# ESP32-C6 register map
Vendor: ESPRESSIF SYSTEMS (SHANGHAI) CO., LTD.; Series: ESP32 C-Series; File version: 12
CPU: RV32IMAC r0p0, little endian, no MPU, no FPU, 0 interrupt priority bits
Address unit: 32 bits
Registers are 32-bit, read-write, reset 0x0 unless marked. A register's access mark holds for its fields unless they carry their own. Offsets are from the block's base; [hi:lo] are bit positions.

## APB_SARADC — SAR (Successive Approximation Register) Analog-to-Digital Converter
Base 0x6000E000
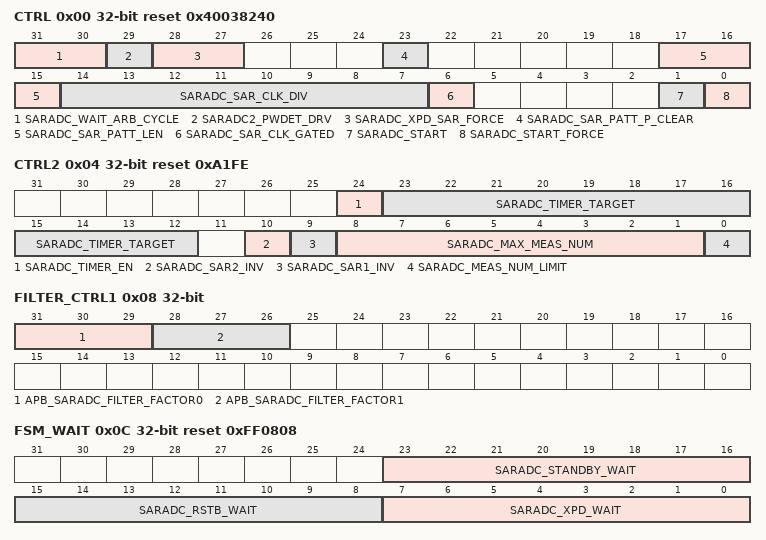
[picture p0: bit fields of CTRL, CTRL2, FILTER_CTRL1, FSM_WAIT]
0x00 CTRL reset 0x40038240 — digital saradc configure register
  [31:30] SARADC_WAIT_ARB_CYCLE — wait arbit signal stable after sar_done
  [29] SARADC2_PWDET_DRV — enable saradc2 power detect driven func.
  [28:27] SARADC_XPD_SAR_FORCE — force option to xpd sar blocks
  [23] SARADC_SAR_PATT_P_CLEAR — clear the pointer of pattern table for DIG ADC1 CTRL
  [17:15] SARADC_SAR_PATT_LEN — 0 ~ 15 means length 1 ~ 16
  [14:7] SARADC_SAR_CLK_DIV — SAR clock divider
  [6] SARADC_SAR_CLK_GATED — SAR clock gated
  [1] SARADC_START — software enable saradc sample
  [0] SARADC_START_FORCE — select software enable saradc sample
0x04 CTRL2 reset 0xA1FE — digital saradc configure register
  [24] SARADC_TIMER_EN — to enable saradc timer trigger
  [23:12] SARADC_TIMER_TARGET — to set saradc timer target
  [10] SARADC_SAR2_INV — 1: data to DIG ADC2 CTRL is inverted, otherwise not
  [9] SARADC_SAR1_INV — 1: data to DIG ADC1 CTRL is inverted, otherwise not
  [8:1] SARADC_MAX_MEAS_NUM — max conversion number
  [0] SARADC_MEAS_NUM_LIMIT — enable max meas num
0x08 FILTER_CTRL1 — digital saradc configure register
  [31:29] APB_SARADC_FILTER_FACTOR0 — Factor of saradc filter0
  [28:26] APB_SARADC_FILTER_FACTOR1 — Factor of saradc filter1
0x0C FSM_WAIT reset 0xFF0808 — digital saradc configure register
  [23:16] SARADC_STANDBY_WAIT, [15:8] SARADC_RSTB_WAIT, [7:0] SARADC_XPD_WAIT
0x10 SAR1_STATUS ro reset 0x20000000 — digital saradc configure register
  [31:0] SARADC_SAR1_STATUS — saradc1 status about data and channel
0x14 SAR2_STATUS ro reset 0x20000000 — digital saradc configure register
  [31:0] SARADC_SAR2_STATUS — saradc2 status about data and channel
0x18 SAR_PATT_TAB1 reset 0xFFFFFF — digital saradc configure register
  [23:0] SARADC_SAR_PATT_TAB1 — item 0 ~ 3 for pattern table 1 (each item one byte)
0x1C SAR_PATT_TAB2 reset 0xFFFFFF — digital saradc configure register
  [23:0] SARADC_SAR_PATT_TAB2 — Item 4 ~ 7 for pattern table 1 (each item one byte)
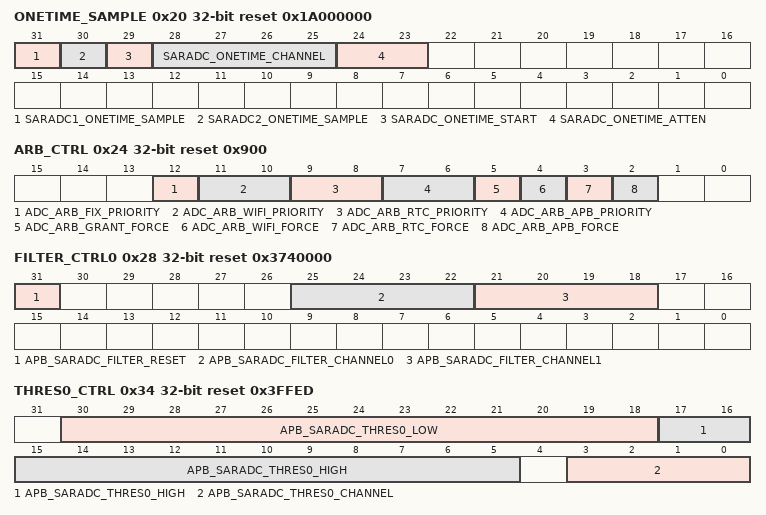
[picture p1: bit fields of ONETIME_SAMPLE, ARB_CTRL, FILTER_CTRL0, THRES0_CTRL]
0x20 ONETIME_SAMPLE reset 0x1A000000 — digital saradc configure register
  [31] SARADC1_ONETIME_SAMPLE — enable adc1 onetime sample
  [30] SARADC2_ONETIME_SAMPLE — enable adc2 onetime sample
  [29] SARADC_ONETIME_START — trigger adc onetime sample
  [28:25] SARADC_ONETIME_CHANNEL — configure onetime channel
  [24:23] SARADC_ONETIME_ATTEN — configure onetime atten
0x24 ARB_CTRL reset 0x900 — digital saradc configure register
  [12] ADC_ARB_FIX_PRIORITY — adc2 arbiter uses fixed priority
  [11:10] ADC_ARB_WIFI_PRIORITY — Set adc2 arbiter wifi priority
  [9:8] ADC_ARB_RTC_PRIORITY — Set adc2 arbiter rtc priority
  [7:6] ADC_ARB_APB_PRIORITY — Set adc2 arbiterapb priority
  [5] ADC_ARB_GRANT_FORCE — adc2 arbiter force grant
  [4] ADC_ARB_WIFI_FORCE — adc2 arbiter force to enable wifi controller
  [3] ADC_ARB_RTC_FORCE — adc2 arbiter force to enable rtc controller
  [2] ADC_ARB_APB_FORCE — adc2 arbiter force to enableapb controller
0x28 FILTER_CTRL0 reset 0x3740000 — digital saradc configure register
  [31] APB_SARADC_FILTER_RESET — enable apb_adc1_filter
  [25:22] APB_SARADC_FILTER_CHANNEL0 — configure filter0 to adc channel
  [21:18] APB_SARADC_FILTER_CHANNEL1 — configure filter1 to adc channel
0x2C SAR1DATA_STATUS ro — digital saradc configure register
  [16:0] APB_SARADC1_DATA — saradc1 data
0x30 SAR2DATA_STATUS ro — digital saradc configure register
  [16:0] APB_SARADC2_DATA — saradc2 data
0x34 THRES0_CTRL reset 0x3FFED — digital saradc configure register
  [30:18] APB_SARADC_THRES0_LOW — saradc thres0 monitor thres
  [17:5] APB_SARADC_THRES0_HIGH — saradc thres0 monitor thres
  [3:0] APB_SARADC_THRES0_CHANNEL — configure thres0 to adc channel
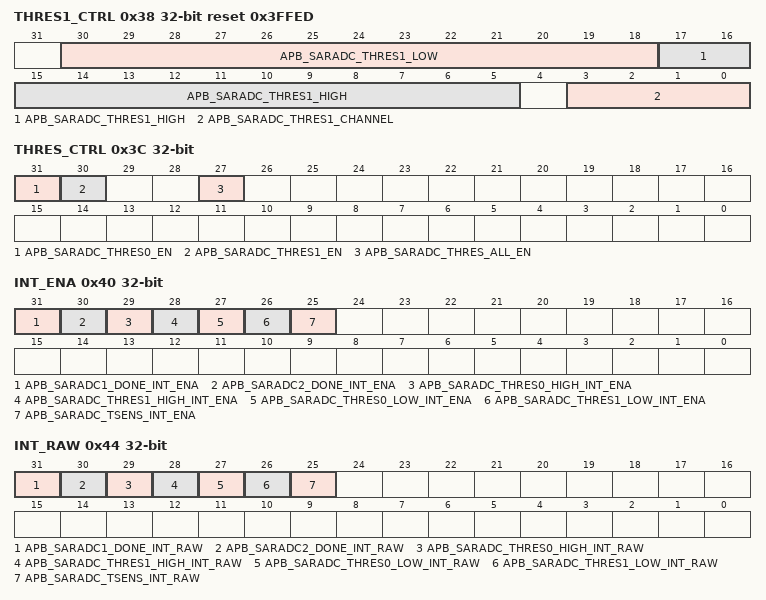
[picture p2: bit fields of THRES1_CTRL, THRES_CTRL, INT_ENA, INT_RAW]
0x38 THRES1_CTRL reset 0x3FFED — digital saradc configure register
  [30:18] APB_SARADC_THRES1_LOW — saradc thres1 monitor thres
  [17:5] APB_SARADC_THRES1_HIGH — saradc thres1 monitor thres
  [3:0] APB_SARADC_THRES1_CHANNEL — configure thres1 to adc channel
0x3C THRES_CTRL — digital saradc configure register
  [31] APB_SARADC_THRES0_EN — enable thres0
  [30] APB_SARADC_THRES1_EN — enable thres1
  [27] APB_SARADC_THRES_ALL_EN — enable thres to all channel
0x40 INT_ENA — digital saradc int register
  [31] APB_SARADC1_DONE_INT_ENA — saradc1 done interrupt enable
  [30] APB_SARADC2_DONE_INT_ENA — saradc2 done interrupt enable
  [29] APB_SARADC_THRES0_HIGH_INT_ENA — saradc thres0 high interrupt enable
  [28] APB_SARADC_THRES1_HIGH_INT_ENA — saradc thres1 high interrupt enable
  [27] APB_SARADC_THRES0_LOW_INT_ENA — saradc thres0 low interrupt enable
  [26] APB_SARADC_THRES1_LOW_INT_ENA — saradc thres1 low interrupt enable
  [25] APB_SARADC_TSENS_INT_ENA — tsens low interrupt enable
0x44 INT_RAW — digital saradc int register
  [31] APB_SARADC1_DONE_INT_RAW — saradc1 done interrupt raw
  [30] APB_SARADC2_DONE_INT_RAW — saradc2 done interrupt raw
  [29] APB_SARADC_THRES0_HIGH_INT_RAW — saradc thres0 high interrupt raw
  [28] APB_SARADC_THRES1_HIGH_INT_RAW — saradc thres1 high interrupt raw
  [27] APB_SARADC_THRES0_LOW_INT_RAW — saradc thres0 low interrupt raw
  [26] APB_SARADC_THRES1_LOW_INT_RAW — saradc thres1 low interrupt raw
  [25] APB_SARADC_TSENS_INT_RAW — saradc tsens interrupt raw
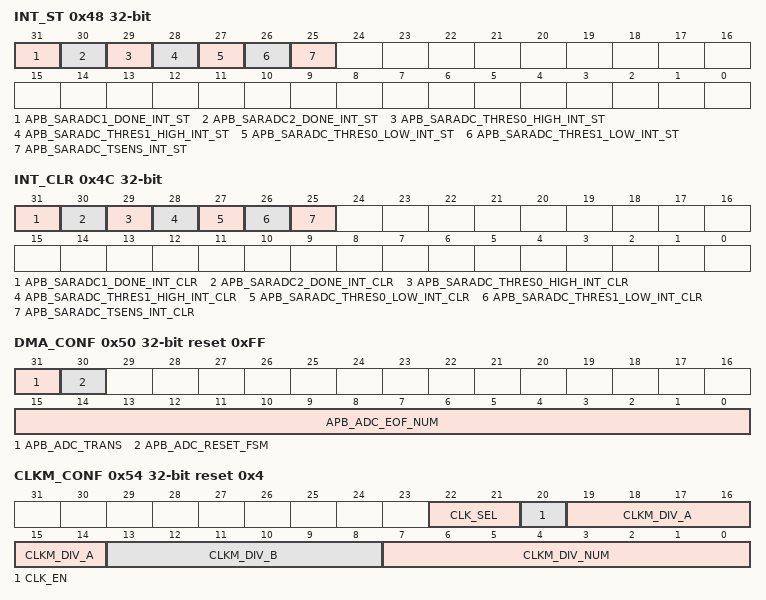
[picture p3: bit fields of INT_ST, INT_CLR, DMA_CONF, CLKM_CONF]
0x48 INT_ST ro — digital saradc int register
  [31] APB_SARADC1_DONE_INT_ST — saradc1 done interrupt state
  [30] APB_SARADC2_DONE_INT_ST — saradc2 done interrupt state
  [29] APB_SARADC_THRES0_HIGH_INT_ST — saradc thres0 high interrupt state
  [28] APB_SARADC_THRES1_HIGH_INT_ST — saradc thres1 high interrupt state
  [27] APB_SARADC_THRES0_LOW_INT_ST — saradc thres0 low interrupt state
  [26] APB_SARADC_THRES1_LOW_INT_ST — saradc thres1 low interrupt state
  [25] APB_SARADC_TSENS_INT_ST — saradc tsens interrupt state
0x4C INT_CLR wo — digital saradc int register
  [31] APB_SARADC1_DONE_INT_CLR — saradc1 done interrupt clear
  [30] APB_SARADC2_DONE_INT_CLR — saradc2 done interrupt clear
  [29] APB_SARADC_THRES0_HIGH_INT_CLR — saradc thres0 high interrupt clear
  [28] APB_SARADC_THRES1_HIGH_INT_CLR — saradc thres1 high interrupt clear
  [27] APB_SARADC_THRES0_LOW_INT_CLR — saradc thres0 low interrupt clear
  [26] APB_SARADC_THRES1_LOW_INT_CLR — saradc thres1 low interrupt clear
  [25] APB_SARADC_TSENS_INT_CLR — saradc tsens interrupt clear
0x50 DMA_CONF reset 0xFF — digital saradc configure register
  [31] APB_ADC_TRANS — enable apb_adc use spi_dma
  [30] APB_ADC_RESET_FSM — reset_apb_adc_state
  [15:0] APB_ADC_EOF_NUM — the dma_in_suc_eof gen when sample cnt = spi_eof_num
0x54 CLKM_CONF reset 0x4 — digital saradc configure register
  [22:21] CLK_SEL — Set this bit to enable clk_apll
  [20] CLK_EN — reg clk en
  [19:14] CLKM_DIV_A — Fractional clock divider denominator value
  [13:8] CLKM_DIV_B — Fractional clock divider numerator value
  [7:0] CLKM_DIV_NUM — Integral I2S clock divider value
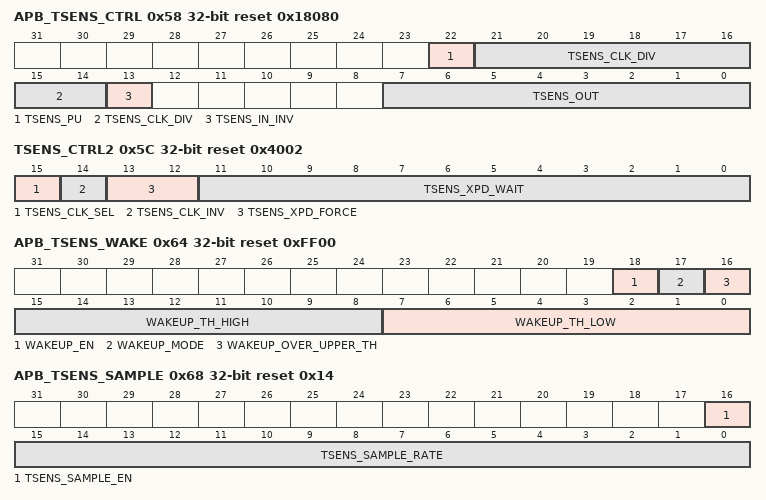
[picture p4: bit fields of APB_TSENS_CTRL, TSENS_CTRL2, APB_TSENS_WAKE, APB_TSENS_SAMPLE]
0x58 APB_TSENS_CTRL access per field reset 0x18080 — digital tsens configure register
  [22] TSENS_PU rw — temperature sensor power up
  [21:14] TSENS_CLK_DIV rw — temperature sensor clock divider
  [13] TSENS_IN_INV rw — invert temperature sensor data
  [7:0] TSENS_OUT ro — temperature sensor data out
0x5C TSENS_CTRL2 reset 0x4002 — digital tsens configure register
  [15] TSENS_CLK_SEL — tsens clk select
  [14] TSENS_CLK_INV — inv tsens clk
  [13:12] TSENS_XPD_FORCE — force power up tsens
  [11:0] TSENS_XPD_WAIT — the time that power up tsens need wait
0x60 CALI reset 0x8000 — digital saradc configure register
  [16:0] APB_SARADC_CALI_CFG — saradc cali factor
0x64 APB_TSENS_WAKE access per field reset 0xFF00 — digital tsens configure register
  [18] WAKEUP_EN rw — reg_wakeup_en
  [17] WAKEUP_MODE rw — reg_wakeup_mode
  [16] WAKEUP_OVER_UPPER_TH ro — reg_wakeup_over_upper_th
  [15:8] WAKEUP_TH_HIGH rw — reg_wakeup_th_high
  [7:0] WAKEUP_TH_LOW rw — reg_wakeup_th_low
0x68 APB_TSENS_SAMPLE reset 0x14 — digital tsens configure register
  [16] TSENS_SAMPLE_EN — HW sample en
  [15:0] TSENS_SAMPLE_RATE — HW sample rate
0x3FC CTRL_DATE reset 0x2206240 — version

## Notices in the file
Copyright 2025 Espressif Systems (Shanghai) PTE LTD
Licensed under the Apache License, Version 2.0 (the "License");
you may not use this file except in compliance with the License.
You may obtain a copy of the License at
http://www.apache.org/licenses/LICENSE-2.0
Unless required by applicable law or agreed to in writing, software
distributed under the License is distributed on an "AS IS" BASIS,
WITHOUT WARRANTIES OR CONDITIONS OF ANY KIND, either express or implied.
See the License for the specific language governing permissions and
limitations under the License.
